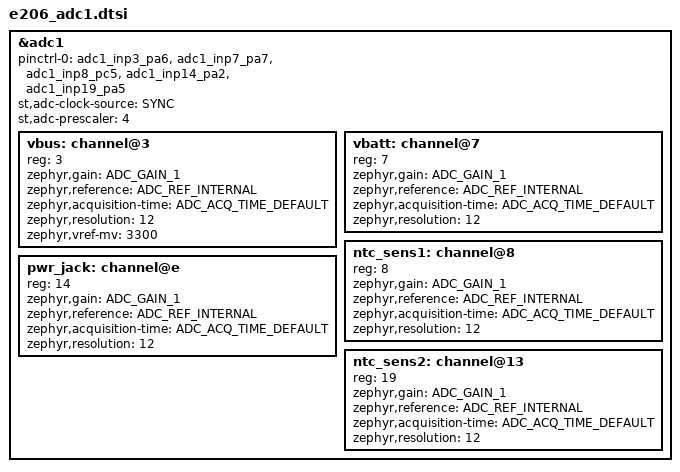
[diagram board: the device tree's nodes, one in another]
/*
 * Copyright (c) 2023 Acme CPU
 *
 */

 &adc1 {
    pinctrl-0 = <&adc1_inp3_pa6 &adc1_inp7_pa7 &adc1_inp8_pc5 &adc1_inp14_pa2 &adc1_inp19_pa5>;
    pinctrl-names = "default";
    st,adc-clock-source = <SYNC>;
    st,adc-prescaler = <4>;
    status = "okay";
    
	#address-cells = <1>;
	#size-cells = <0>;
	
	vbus: channel@3 {
		reg = <3>;
		zephyr,gain = "ADC_GAIN_1";
		zephyr,reference = "ADC_REF_INTERNAL";
		zephyr,acquisition-time = <ADC_ACQ_TIME_DEFAULT>;
		zephyr,resolution = <12>;
		zephyr,vref-mv = <3300>;
	};

	vbatt: channel@7 {
		reg = <7>;
		zephyr,gain = "ADC_GAIN_1";
		zephyr,reference = "ADC_REF_INTERNAL";
		zephyr,acquisition-time = <ADC_ACQ_TIME_DEFAULT>;
		zephyr,resolution = <12>;
	};
	
	ntc_sens1: channel@8 {
		reg = <8>;
		zephyr,gain = "ADC_GAIN_1";
		zephyr,reference = "ADC_REF_INTERNAL";
		zephyr,acquisition-time = <ADC_ACQ_TIME_DEFAULT>;
		zephyr,resolution = <12>;
	};
	
	pwr_jack: channel@e {
		reg = <14>;
		zephyr,gain = "ADC_GAIN_1";
		zephyr,reference = "ADC_REF_INTERNAL";
		zephyr,acquisition-time = <ADC_ACQ_TIME_DEFAULT>;
		zephyr,resolution = <12>;
	};
	
	ntc_sens2: channel@13 {
		reg = <19>;
		zephyr,gain = "ADC_GAIN_1";
		zephyr,reference = "ADC_REF_INTERNAL";
		zephyr,acquisition-time = <ADC_ACQ_TIME_DEFAULT>;
		zephyr,resolution = <12>;
	};
};
 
